# A8107M register map
Vendor: Amiccom Electronics Co., Ltd.; Series: A8107M; File version: 1.0
CPU: CM0 r0p0, little endian, no MPU, no FPU, 2 interrupt priority bits
Registers are 32-bit, read-write, reset 0x0 unless marked. A register's access mark holds for its fields unless they carry their own. Offsets are from the block's base; [hi:lo] are bit positions.

## DUALTIMER2 — Dual Timer
Base 0x40002020
0x00 DUALTMR2_LOAD — Dual Timer 2 Load register
0x04 DUALTMR2_VALUE — Dual Timer 2 current Value register
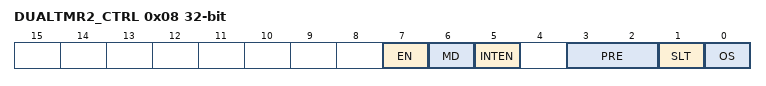
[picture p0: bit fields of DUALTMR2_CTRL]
0x08 DUALTMR2_CTRL (reset mask 0xF) — Dual Timer 2 Control register
  [7] EN — Dual timer x Enable
    0=Disable; 1=Enable (Dual timer start count down)
  [6] MD — Dual timer Mode
    0=Free-running mode; 1=Periodic mode
  [5] INTEN — Dual timer interrupt enable
    0=Dual Timer interrupt disable; 1=Dual Timer interrupt enable
  [3:2] PRE — Dual timer size selects 16-bit or 32-bit counter operation
    0=Dual timer prescale (Clock is divided by 1); 1=Dual timer prescale (Clock is divided by 16); 2=Dual timer prescale (Clock is divided by 256); 3=Dual timer prescale (Undefined)
  [1] SLT — Dual timer size selects 16-bit or 32-bit counter operation
    0=16-bit counter; 1=32-bit counter
  [0] OS — Dual timer one-shot count selects
    0=Wrapping; 1=One-shot
0x0C DUALTMR2_INTCLR wo — Dual Timer 2 Interrupt Clear register
  [0] INTCLR — Timer interrupt clear. Write any value to this register to clean RIS and MIS.
    0=Timer interrupt clear; 1=Timer interrupt clear
0x10 DUALTMR2_RIS ro — Dual Timer 2 Raw Interrupt register
  [0] RIS — Dual timer Raw interrupt status
    0=VALUE[31:0] not counts down to 0; 1=VALUE[31:0] had counted down to 0
0x14 DUALTMR2_MIS ro — Dual Timer 2 Mask Interrupt register
  [0] MIS — Dual timer interrupt enabled status from the counter
    0=INTEN=0 or RIS=0. Dual Timer interrupt not occur; 1=INTEN=1 and RIS=1. Dual Timer interrupt occur
0x18 DUALTMR2_BGLOAD — Dual Timer 2 Back Ground Load register

## UART0 — Timer
Base 0x40004000
Same registers: UART1 0x40005000, UART2 0x40006000
0x00 UART_DATA (reset mask 0xFF)
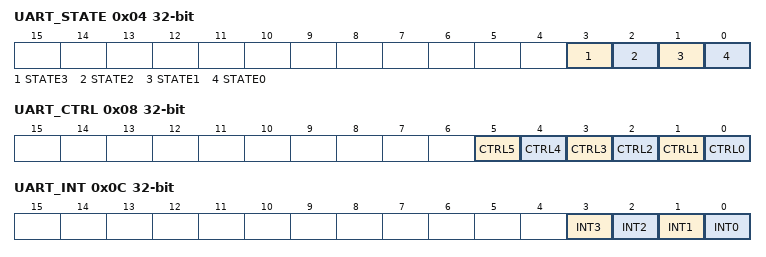
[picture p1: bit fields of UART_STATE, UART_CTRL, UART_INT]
0x04 UART_STATE — UART Status Register
  [3] STATE3 — RX buffer overrun
    0=RX Buffer does not overrun; 1=RX Buffer has overrun. Write 1 to clean this bit
  [2] STATE2 — TX buffer overrun
    0=TX Buffer does not overrun; 1=TX Buffer has overrun. Write 1 to clean this bit
  [1] STATE1 ro — RX buffer full
    0=RX buffer not full; 1=RX buffer full
  [0] STATE0 ro — TX buffer full
    0=TX buffer not full; 1=TX buffer full
0x08 UART_CTRL — UART Control Register
  [5] CTRL5 — RX overrun interrupt enable
    0=Disable UART RX overrun interrupt; 1=Enable UART RX overrun interrupt
  [4] CTRL4 — TX overrun interrupt enable
    0=Disable UART TX overrun interrupt; 1=Enable UART TX overrun interrupt
  [3] CTRL3 — RX buffer overrun
    0=Disable UART RX interrupt; 1=Enable UART RX interrupt
  [2] CTRL2 — TX interrupt enable
    0=Disable UART TX interrupt; 1=Enable UART TX interrupt
  [1] CTRL1 — RX enable
    0=Disable UART RX; 1=Enable UART RX
  [0] CTRL0 — TX enable
    0=Disable UART TX; 1=Enable UART TX
0x0C UART_INT — UART interrupt state and clear Register
  [3] INT3 — RX buffer overrun
    0=RX overrun interrupt does not occur; 1=RX overrun interrupt has occurred. Write 1 to clear this bit
  [2] INT2 — TX overrun interrupt
    0=TX overrun interrupt does not occur; 1=TX overrun interrupt has occurred. Write 1 to clear this bit
  [1] INT1 — RX interrupt
    0=RX interrupt does not occur; 1=RX interrupt has occurred. Write 1 to clear this bit
  [0] INT0 — TX interrupt
    0=TX interrupt does not occur; 1=TX interrupt has occurred. Write 1 to clear this bit
0x10 UART_BAUDDIV (reset mask 0xFFFFF) — UART Baud rate divider register

## WATCHDOG
Base 0x40008000
0x00 WDOGLOAD — Watchdog Load Register
0x04 WDOGVALUE ro — Watchdog Value Register
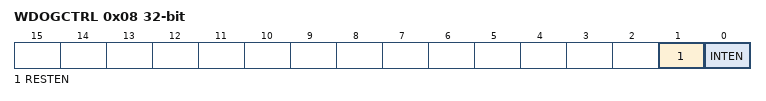
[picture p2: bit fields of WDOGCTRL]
0x08 WDOGCTRL — Watchdog Control Register
  [1] RESTEN — Enable watchdog reset
    0=Watchdog reset disable; 1=Watchdog reset enable
  [0] INTEN — Watchdog counter and interrupt enable
    0=Disable counter and interrupt; 1=Enable counter and interrupt
0x0C WDOGINTCLR wo — Watchdog Interrupt Clean Register
  [31:0] INTCLR rw — A write of any value to clear the watchdog interrupt, and reloads the counter from the value in LOAD.
0x10 WDOGRIS read-onlye — Watchdog Raw Interrupt Status Register
  [0] RAWINTSTAT ro — Raw Watchdog Interrupt Raw interrupt status from the counter
    0=Raw watchdog interrupt not occur; 1=Raw watchdog Interrupt occur
0x14 WDOGMIS read-onlye — Watchdog Enabled Interrupt Status Register
  [0] MASKINTSTAT ro — Watchdog Interrupt Enabled interrupt status from the counter
    0=Watchdog interrupt not occur; 1=Watchdog Interrupt occur
0xC00 WDOGLOCK — Watchdog Lock Register
  [31:0] LOCK — Enable register writes Enable write access to all other registers by writing 0x1ACCE551. Disable write access by writing any other value.
0xF00 ITCR — Watchdog Integration Test Control Register
0xF04 ITOP wo — Watchdog Integration Test Output Set Register
